VERSION ""

NS_ :

BS_:

BU_: ECU PowerNode1 PowerNode2 AnalogNode1 AnalogNode2 DashBoard IMU

BO_ 3221225472 VECTOR__INDEPENDENT_SIG_MSG: 0 Vector__XXX
 SG_ Select : 7|8@0+ (1,0) [0|0] "" Vector__XXX
 SG_ NewSignal_0001 : 15|8@0+ (1,0) [0|0] "" Vector__XXX
 SG_ NewSignal_0002 : 0|8@1+ (1,0) [0|0] "" Vector__XXX

BO_ 25 Over_Current_PN1: 2 PowerNode1

BO_ 23 Under_Current_PN1: 2 PowerNode1

BO_ 24 Warning_Current_PN1: 2 PowerNode1

BO_ 28 Over_Current_PN2: 2 PowerNode2

BO_ 27 Under_Current_PN2: 2 PowerNode2

BO_ 26 Warning_Current_PN2: 2 PowerNode2

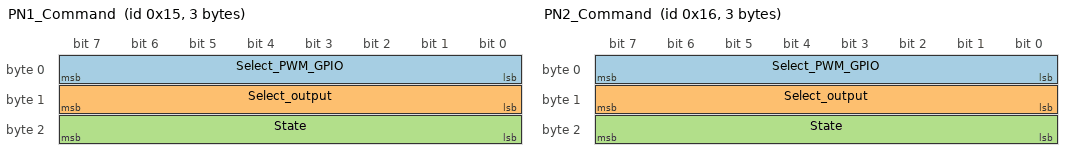
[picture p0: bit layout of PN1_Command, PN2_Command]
BO_ 21 PN1_Command: 3 ECU
 SG_ Select_PWM_GPIO : 0|8@1+ (1,0) [0|0] "" Vector__XXX
 SG_ Select_output : 8|8@1+ (1,0) [0|0] "" Vector__XXX
 SG_ State : 16|8@1+ (1,0) [0|0] "" Vector__XXX

BO_ 22 PN2_Command: 3 ECU
 SG_ Select_PWM_GPIO : 0|8@1+ (1,0) [0|0] "" Vector__XXX
 SG_ Select_output : 8|8@1+ (1,0) [0|0] "" Vector__XXX
 SG_ State : 16|8@1+ (1,0) [0|0] "" Vector__XXX

BO_ 1 APPS1: 2 AnalogNode1
 SG_ Value : 0|16@1+ (1,0) [0|0] "" Vector__XXX

BO_ 2 APPS2: 2 AnalogNode1
 SG_ Value : 0|16@1+ (1,0) [0|0] "" Vector__XXX

BO_ 3 BPPS: 2 AnalogNode1
 SG_ Value : 0|16@1+ (1,0) [0|0] "" Vector__XXX

BO_ 4 BrakeFront: 2 AnalogNode1
 SG_ Value : 0|16@1+ (1,0) [0|0] "" Vector__XXX

BO_ 5 BrakeRear: 2 AnalogNode2
 SG_ Value : 0|16@1+ (1,0) [0|0] "" Vector__XXX

BO_ 7 WaterLevel: 2 AnalogNode2
 SG_ Value : 0|16@1+ (1,0) [0|0] "" Vector__XXX

BO_ 9 HeavesRear: 2 AnalogNode2
 SG_ Value : 0|16@1+ (1,0) [0|0] "" Vector__XXX

BO_ 10 Rolls1: 2 AnalogNode1
 SG_ Value : 0|16@1+ (1,0) [0|0] "" Vector__XXX

BO_ 11 Rolls2: 2 AnalogNode2
 SG_ Value : 0|16@1+ (1,0) [0|0] "" Vector__XXX

BO_ 8 HeavesFront: 2 AnalogNode1
 SG_ Value : 0|16@1+ (1,0) [0|0] "" Vector__XXX

BO_ 6 Steering_Angle: 2 AnalogNode1
 SG_ Value : 0|16@1+ (1,0) [0|0] "" Vector__XXX

BO_ 160 Entering_Idle_State: 1 ECU

BO_ 161 TS_OFF: 1 ECU

BO_ 162 TS_BAD: 1 ECU

BO_ 163 Critical_Error: 1 ECU

BO_ 164 Ready_to_enable_TS: 1 ECU

BO_ 165 TS_Activation_Req_Ready: 1 ECU

BO_ 166 TS_Activation_Req_NReady: 1 ECU

BO_ 167 Entering_Startup_State: 1 ECU

BO_ 168 BMS_Fail: 1 ECU

BO_ 169 IVT_Fail: 1 ECU

BO_ 170 Readyness_Power_Fail: 1 ECU

BO_ 171 Entering_Readyness_Check_State: 1 ECU

BO_ 172 Errorplace_too_many_loops: 1 ECU

BO_ 173 Entering_PreOperational_State: 1 ECU

BO_ 174 Power_request: 1 ECU

BO_ 175 Power_off_to_inverters_req: 1 ECU

BO_ 176 Start_Pressed: 1 ECU

BO_ 177 RDTM_Pressed: 1 ECU

BO_ 178 Entering_RDTM_State: 1 ECU

BO_ 179 RTDM_TA: 1 ECU

BO_ 180 Dissabling_Regen: 1 ECU

BO_ 181 Entering_TS_Active_State: 1 ECU

BO_ 182 TS_LoV: 1 ECU

BO_ 183 TS_On: 1 ECU

BO_ 184 RDTM_Activation_with_no_braking: 1 ECU

BO_ 185 Waiting_Precharge: 1 ECU

BO_ 186 Idle_State_Req: 1 ECU

BO_ 187 Entering_Error_State: 1 ECU

BO_ 12 BTN1: 1 AnalogNode1
 SG_ Value : 0|16@1+ (1,0) [0|0] "" Vector__XXX

BO_ 13 BTN2: 1 AnalogNode1
 SG_ Value : 0|16@1+ (1,0) [0|0] "" Vector__XXX

BO_ 14 BTN3: 1 AnalogNode1
 SG_ Value : 0|16@1+ (1,0) [0|0] "" Vector__XXX

BO_ 29 PN1_Device_Status: 1 PowerNode1

BO_ 30 PN2_Device_Status: 1 PowerNode2

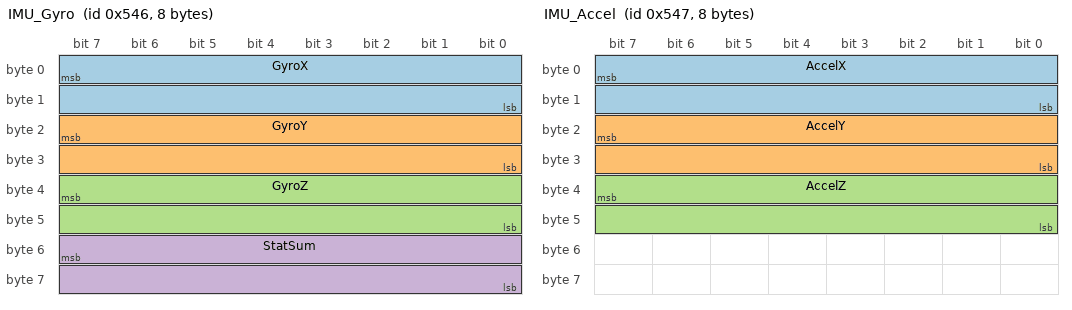
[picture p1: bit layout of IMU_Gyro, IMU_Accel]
BO_ 1350 IMU_Gyro: 8 IMU
 SG_ GyroX : 7|16@0- (0.01,0) [-327.68|327.67] "deg/s" ECU
 SG_ GyroY : 23|16@0- (0.01,0) [-327.68|327.67] "deg/s" ECU
 SG_ GyroZ : 39|16@0- (0.01,0) [-327.68|327.67] "deg/s" ECU
 SG_ StatSum : 55|16@0+ (1,0) [0|65535] "" ECU

BO_ 1351 IMU_Accel: 8 IMU
 SG_ AccelX : 7|16@0- (0.01,0) [-327.68|327.67] "m/s^2" ECU
 SG_ AccelY : 23|16@0- (0.01,0) [-327.68|327.67] "m/s^2" ECU
 SG_ AccelZ : 39|16@0- (0.01,0) [-327.68|327.67] "m/s^2" ECU

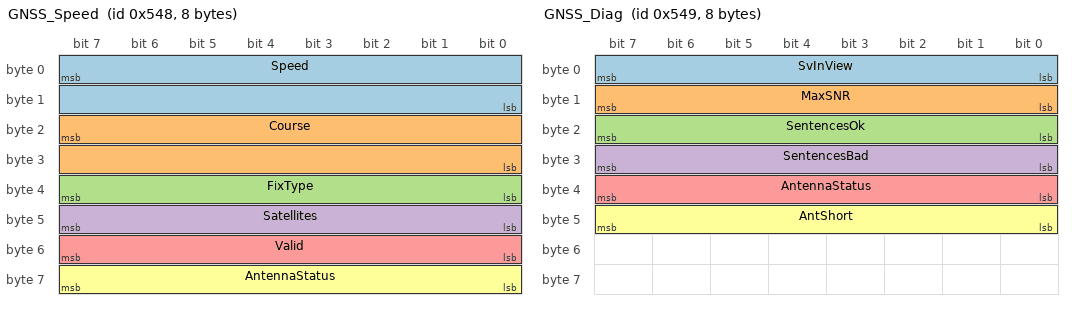
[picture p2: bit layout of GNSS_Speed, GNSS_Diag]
BO_ 1352 GNSS_Speed: 8 IMU
 SG_ Speed : 7|16@0+ (0.001,0) [0|65.535] "m/s" ECU
 SG_ Course : 23|16@0- (0.1,0) [0|360] "deg" ECU
 SG_ FixType : 39|8@0+ (1,0) [0|255] "" ECU
 SG_ Satellites : 47|8@0+ (1,0) [0|255] "" ECU
 SG_ Valid : 55|8@0+ (1,0) [0|1] "" ECU
 SG_ AntennaStatus : 63|8@0+ (1,0) [0|255] "" ECU

BO_ 1353 GNSS_Diag: 8 IMU
 SG_ SvInView : 7|8@0+ (1,0) [0|255] "" Vector__XXX
 SG_ MaxSNR : 15|8@0+ (1,0) [0|255] "dBHz" Vector__XXX
 SG_ SentencesOk : 23|8@0+ (1,0) [0|255] "" Vector__XXX
 SG_ SentencesBad : 31|8@0+ (1,0) [0|255] "" Vector__XXX
 SG_ AntennaStatus : 39|8@0+ (1,0) [0|255] "" Vector__XXX
 SG_ AntShort : 47|8@0+ (1,0) [0|1] "" Vector__XXX

BO_ 1354 GNSS_Position: 8 IMU
 SG_ Latitude : 7|32@0- (1E-007,0) [-90|90] "deg" ECU
 SG_ Longitude : 39|32@0- (1E-007,0) [-180|180] "deg" ECU

BO_ 1355 IMU_Status: 8 IMU
 SG_ StatCom : 7|16@0+ (1,0) [0|65535] "" Vector__XXX
 SG_ StatRateX : 23|16@0+ (1,0) [0|65535] "" Vector__XXX

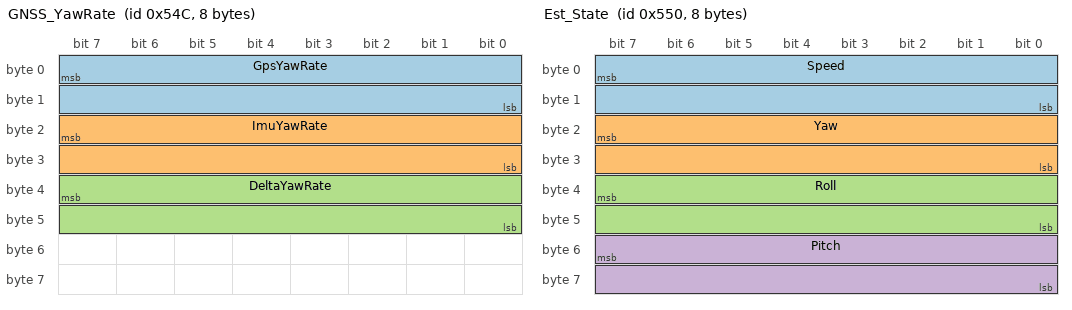
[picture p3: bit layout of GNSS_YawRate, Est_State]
BO_ 1356 GNSS_YawRate: 8 IMU
 SG_ GpsYawRate : 7|16@0- (0.01,0) [-327.68|327.67] "deg/s" Vector__XXX
 SG_ ImuYawRate : 23|16@0- (0.01,0) [-327.68|327.67] "deg/s" Vector__XXX
 SG_ DeltaYawRate : 39|16@0- (0.01,0) [-327.68|327.67] "deg/s" Vector__XXX

BO_ 1360 Est_State: 8 IMU
 SG_ Speed : 7|16@0- (0.001,0) [-32.768|32.767] "m/s" ECU
 SG_ Yaw : 23|16@0- (0.01,0) [-327.68|327.67] "deg" ECU
 SG_ Roll : 39|16@0- (0.01,0) [-327.68|327.67] "deg" ECU
 SG_ Pitch : 55|16@0- (0.01,0) [-327.68|327.67] "deg" ECU

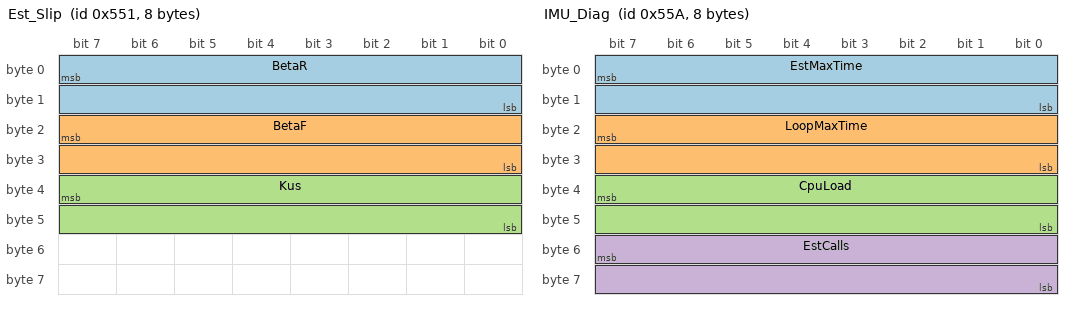
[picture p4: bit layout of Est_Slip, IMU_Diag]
BO_ 1361 Est_Slip: 8 IMU
 SG_ BetaR : 7|16@0- (0.001,0) [-32.768|32.767] "rad" ECU
 SG_ BetaF : 23|16@0- (0.001,0) [-32.768|32.767] "rad" ECU
 SG_ Kus : 39|16@0- (0.001,0) [-32.768|32.767] "rad" ECU

BO_ 1370 IMU_Diag: 8 IMU
 SG_ EstMaxTime : 7|16@0+ (1,0) [0|65535] "us" Vector__XXX
 SG_ LoopMaxTime : 23|16@0+ (1,0) [0|65535] "us" Vector__XXX
 SG_ CpuLoad : 39|16@0+ (0.1,0) [0|100] "%" Vector__XXX
 SG_ EstCalls : 55|16@0+ (1,0) [0|65535] "" Vector__XXX

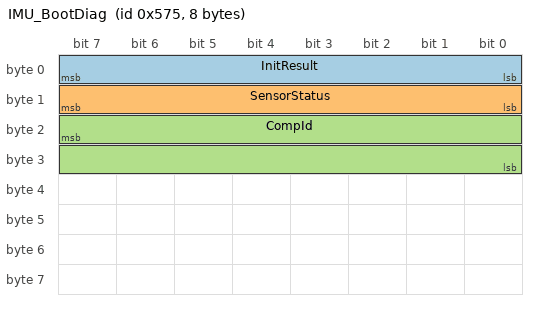
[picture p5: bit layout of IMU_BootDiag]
BO_ 1397 IMU_BootDiag: 8 IMU
 SG_ InitResult : 7|8@0+ (1,0) [0|3] "" Vector__XXX
 SG_ SensorStatus : 15|8@0+ (1,0) [0|3] "" Vector__XXX
 SG_ CompId : 23|16@0+ (1,0) [0|65535] "" Vector__XXX

BO_ 1399 IMU_Boot: 8 IMU
 SG_ Heartbeat : 7|16@0+ (1,0) [0|65535] "" Vector__XXX

CM_ BO_ 1350 "IMU board SCH16T gyro, 100 Hz";
CM_ SG_ 1350 GyroZ "Yaw rate, positive = turning left (CCW seen from above) if board Z axis points up";
CM_ BO_ 1352 "GNSS speed/course, sent once per RMC sentence";
CM_ SG_ 1352 Speed "Sent as int16 mm/s by IMU board, decode unsigned so speeds above 32.767 m/s do not wrap negative";
CM_ SG_ 1352 FixType "0 = no fix";
CM_ BO_ 1360 "Estimator state, sent after every estimator step";
CM_ SG_ 1360 Speed "Overflows above 32.767 m/s";
CM_ BO_ 1397 "Sent once at IMU board boot";
CM_ SG_ 1397 CompId "0x0000 = SPI not reaching sensor";
CM_ BO_ 1399 "Boot heartbeat, 0xB007";
VAL_ 1397 InitResult 0 "HAL_OK" 1 "HAL_ERROR" 2 "HAL_BUSY" 3 "HAL_TIMEOUT" ;
VAL_ 1397 SensorStatus 0 "Normal" 1 "Error" 2 "Saturation" 3 "Init" ;
